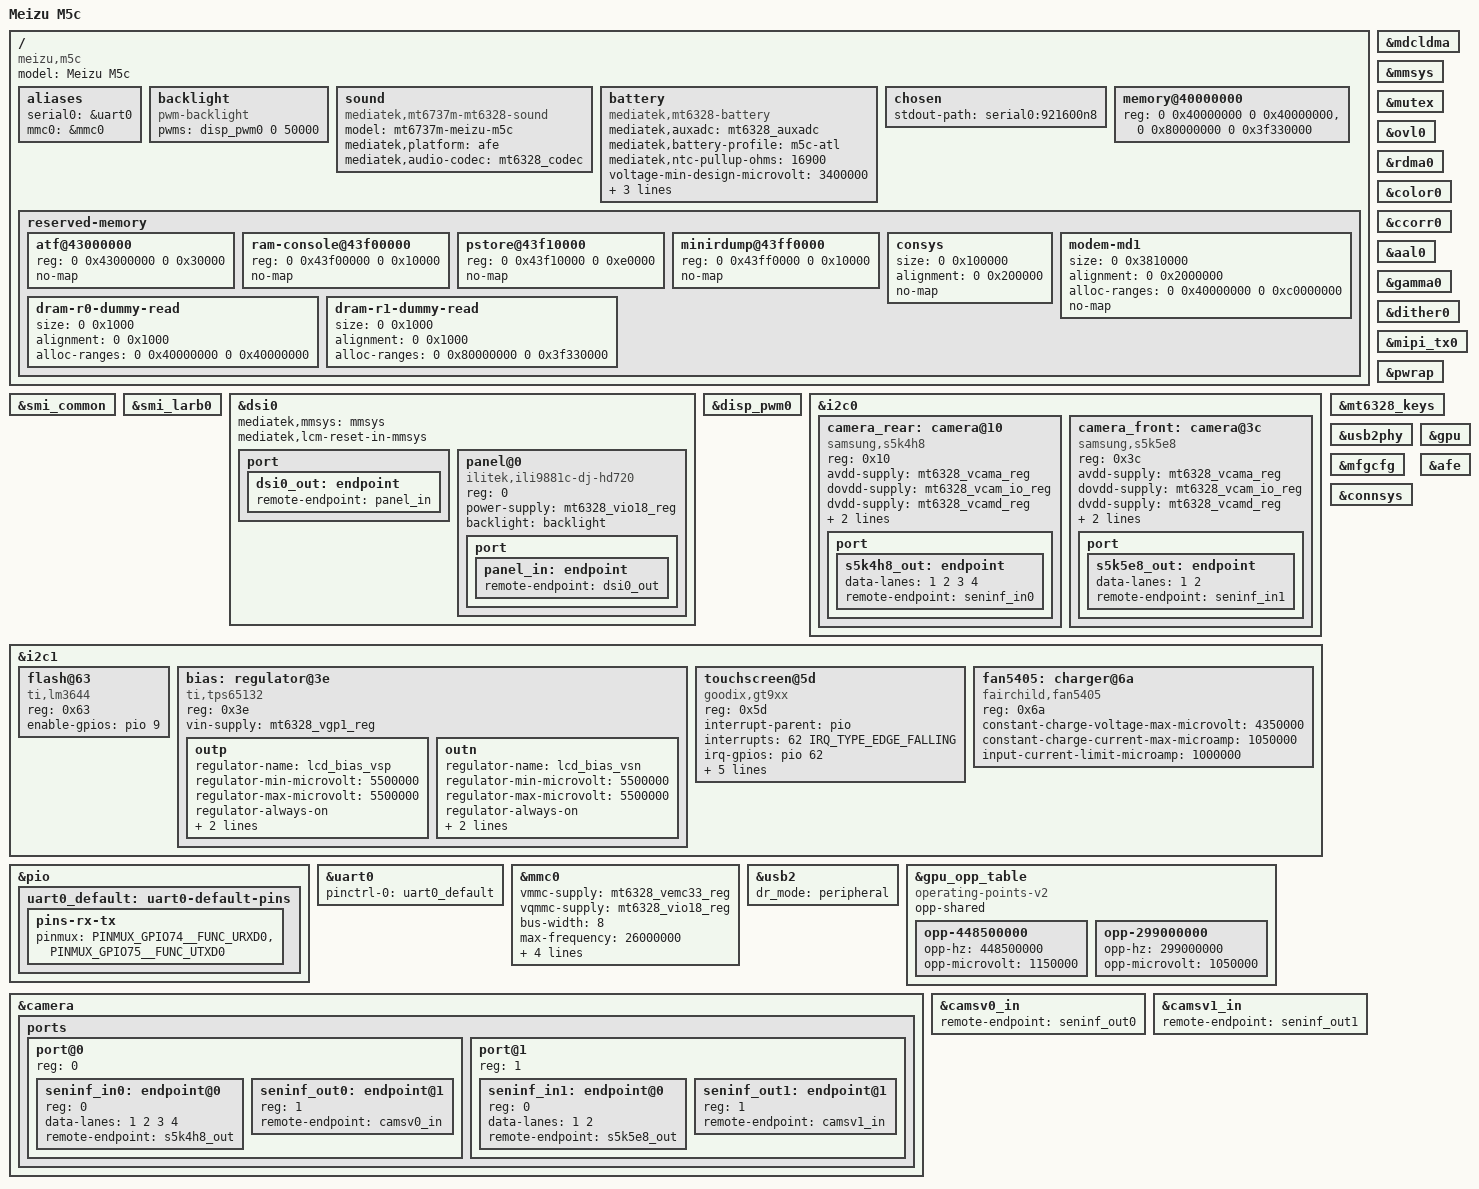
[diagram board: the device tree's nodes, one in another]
// SPDX-License-Identifier: BSD-3-Clause
/dts-v1/;

#include <dt-bindings/gpio/gpio.h>

#include "mt6737m.dtsi"
#include "mt6328.dtsi"

/ {
	model = "Meizu M5c";
	compatible = "meizu,m5c", "mediatek,mt6737m";

	aliases {
		serial0 = &uart0;
		mmc0 = &mmc0;
	};

	/*
	 * Backlight on DISP_PWM channel 0.
	 * UNPROVEN: the stock board only provides led_mode = <5> and
	 * pwm_config = <0 0 0 0 0>; the 20 kHz period is a placeholder and
	 * the PWM output pin/pinmux is not known yet.
	 */
	backlight: backlight {
		compatible = "pwm-backlight";
		pwms = <&disp_pwm0 0 50000>;
	};

	sound {
		compatible = "mediatek,mt6737m-mt6328-sound";
		model = "mt6737m-meizu-m5c";
		mediatek,platform = <&afe>;
		mediatek,audio-codec = <&mt6328_codec>;
	};

	battery: battery {
		compatible = "mediatek,mt6328-battery";
		mediatek,auxadc = <&mt6328_auxadc>;
		mediatek,battery-profile = "m5c-atl";
		mediatek,ntc-pullup-ohms = <16900>;
		voltage-min-design-microvolt = <3400000>;
		voltage-max-design-microvolt = <4350000>;
		charge-current-max-microamp = <1050000>;
		charger = <&fan5405>;
	};

	chosen {
		stdout-path = "serial0:921600n8";
	};

	memory@40000000 {
		device_type = "memory";
		reg = <0 0x40000000 0 0x40000000>,
		      <0 0x80000000 0 0x3f330000>;
	};

	reserved-memory {
		#address-cells = <2>;
		#size-cells = <2>;
		ranges;

		atf@43000000 {
			reg = <0 0x43000000 0 0x30000>;
			no-map;
		};

		ram-console@43f00000 {
			reg = <0 0x43f00000 0 0x10000>;
			no-map;
		};

		pstore@43f10000 {
			reg = <0 0x43f10000 0 0xe0000>;
			no-map;
		};

		minirdump@43ff0000 {
			reg = <0 0x43ff0000 0 0x10000>;
			no-map;
		};

		consys {
			size = <0 0x100000>;
			alignment = <0 0x200000>;
			no-map;
		};

		/*
		 * MD1 cellular modem DRAM: firmware image plus the shared
		 * memory window in one contiguous extents (vendor
		 * reserve-memory-ccci_md1 size = md_size+smem_size,
		 * 0x3810000 bytes). Linux must never allocate from it.
		 */
		modem-md1 {
			size = <0 0x3810000>;
			alignment = <0 0x2000000>;
			alloc-ranges = <0 0x40000000 0 0xc0000000>;
			no-map;
		};

		dram-r0-dummy-read {
			size = <0 0x1000>;
			alignment = <0 0x1000>;
			alloc-ranges = <0 0x40000000 0 0x40000000>;
		};

		dram-r1-dummy-read {
			size = <0 0x1000>;
			alignment = <0 0x1000>;
			alloc-ranges = <0 0x80000000 0 0x3f330000>;
		};
	};
};

/*
 * MD1 cellular modem. The CLDMA and CCIF blocks come from the mt6735.dtsi
 * node; this board only has to enable it, the transport clocks are optional.
 */
&mdcldma {
	status = "okay";
};

/*
 * Display skeleton for the m5c (MT6737M).  All register data comes from the
 * vendor 4.9 tree; this has never been run on hardware.  There is no
 * power-domains/scpsys node yet and no SMI larb0/iommu, so the DISP domain
 * and the SMI gates are left as LK configured them.
 */
&mmsys {
	status = "okay";
};

&smi_common {
	status = "okay";
};

&smi_larb0 {
	status = "okay";
};

&mutex {
	status = "okay";
};

&ovl0 {
	status = "okay";
};

&rdma0 {
	status = "okay";
};

&color0 {
	status = "okay";
};

&ccorr0 {
	status = "okay";
};

&aal0 {
	status = "okay";
};

&gamma0 {
	status = "okay";
};

&dither0 {
	status = "okay";
};

/*
 * DSI0: the panel reset is MMSYS+0x150 bit 0 (LCM_RST_B), not a GPIO, see
 * the mtk_dsi quirk.  Panel timing/init table live in
 * panel-ilitek-ili9881c.c (ilitek,ili9881c-dj-hd720).
 */
&dsi0 {
	status = "okay";
	mediatek,mmsys = <&mmsys>;
	mediatek,lcm-reset-in-mmsys;

	port {
		dsi0_out: endpoint {
			remote-endpoint = <&panel_in>;
		};
	};

	panel@0 {
		compatible = "ilitek,ili9881c-dj-hd720";
		reg = <0>;

		/*
		 * UNPROVEN: VGP1 is what the vendor switches in lcm_init_power()
		 * and is used here as the bias chip VIN; the panel VDDI/IOVCC is
		 * assumed to be the always-on VIO18 rail.  The panel driver only
		 * models one supply.
		 */
		power-supply = <&mt6328_vio18_reg>;
		backlight = <&backlight>;

		port {
			panel_in: endpoint {
				remote-endpoint = <&dsi0_out>;
			};
		};
	};
};

&mipi_tx0 {
	status = "okay";
};

&disp_pwm0 {
	status = "okay";
};

&i2c0 {
	status = "okay";

	/*
	 * Rear camera: Samsung S5K4H8 (8 Mpix, 4-lane CSI-2) at 0x10 on i2c0.
	 * Stock pins: CMRST = GPIO44, CMPDN = GPIO7.
	 */
	camera_rear: camera@10 {
		compatible = "samsung,s5k4h8";
		reg = <0x10>;
		avdd-supply = <&mt6328_vcama_reg>;
		dovdd-supply = <&mt6328_vcam_io_reg>;
		dvdd-supply = <&mt6328_vcamd_reg>;
		reset-gpios = <&pio 44 GPIO_ACTIVE_LOW>;
		powerdown-gpios = <&pio 7 GPIO_ACTIVE_LOW>;

		port {
			s5k4h8_out: endpoint {
				data-lanes = <1 2 3 4>;
				remote-endpoint = <&seninf_in0>;
			};
		};
	};

	/*
	 * Front camera: Samsung S5K5E8 (5 Mpix, 2-lane CSI-2) at 0x3c on i2c0.
	 * Stock pins: CMRST1 = GPIO11, CMPDN1 = GPIO12.
	 */
	camera_front: camera@3c {
		compatible = "samsung,s5k5e8";
		reg = <0x3c>;
		avdd-supply = <&mt6328_vcama_reg>;
		dovdd-supply = <&mt6328_vcam_io_reg>;
		dvdd-supply = <&mt6328_vcamd_reg>;
		reset-gpios = <&pio 11 GPIO_ACTIVE_LOW>;
		powerdown-gpios = <&pio 12 GPIO_ACTIVE_LOW>;

		port {
			s5k5e8_out: endpoint {
				data-lanes = <1 2>;
				remote-endpoint = <&seninf_in1>;
			};
		};
	};
};

&i2c1 {
	status = "okay";

	/*
	 * Rear camera flash controller (stock strobe_main@63 on i2c1,
	 * hardware enable on GPIO9).
	 */
	flash@63 {
		compatible = "ti,lm3644", "mediatek,strobe_main";
		reg = <0x63>;
		enable-gpios = <&pio 9 GPIO_ACTIVE_HIGH>;
	};

	/*
	 * TPS65132 bias.  Vendor: i2c1 0x3e, ENP GPIO64, ENN GPIO63, both
	 * driven high to enable (bridge-stock.dts:2327-2368).
	 */
	bias: regulator@3e {
		compatible = "ti,tps65132";
		reg = <0x3e>;
		vin-supply = <&mt6328_vgp1_reg>;

		outp {
			regulator-name = "lcd_bias_vsp";
			/* vendor writes reg 0x00 = 0x0f -> 4.0 V + 15 * 100 mV */
			regulator-min-microvolt = <5500000>;
			regulator-max-microvolt = <5500000>;
			regulator-always-on;
			enable-gpios = <&pio 64 GPIO_ACTIVE_HIGH>;
			/* driver requires the property even without a discharge GPIO */
			ti,active-discharge-time-us = <0>;
		};

		outn {
			regulator-name = "lcd_bias_vsn";
			/* vendor writes reg 0x01 = 0x0f -> -5.5 V */
			regulator-min-microvolt = <5500000>;
			regulator-max-microvolt = <5500000>;
			regulator-always-on;
			enable-gpios = <&pio 63 GPIO_ACTIVE_HIGH>;
			ti,active-discharge-time-us = <0>;
		};
	};

	/*
	 * GT9XXTB touch.  Vendor: i2c1 0x5d, EINT GPIO62, reset GPIO10.
	 * The mainline goodix driver reads the id string at runtime
	 * ("GT9XXTB..." on this panel), so gt911 is only the match fallback.
	 * reset-gpios and irq-gpios are ACTIVE_HIGH because the goodix driver
	 * drives both lines freely during its reset/address-strap sequence.
	 */
	touchscreen@5d {
		compatible = "goodix,gt9xx", "goodix,gt911";
		reg = <0x5d>;
		interrupt-parent = <&pio>;
		interrupts = <62 IRQ_TYPE_EDGE_FALLING>;
		interrupt-names = "irq";
		irq-gpios = <&pio 62 GPIO_ACTIVE_HIGH>;
		reset-gpios = <&pio 10 GPIO_ACTIVE_HIGH>;
		AVDD28-supply = <&mt6328_vgp1_reg>;
		VDDIO-supply = <&mt6328_vio18_reg>;
		touchscreen-size-x = <720>;
		touchscreen-size-y = <1280>;
	};

	/* Fairchild FAN5405 switching charger on i2c1 @ 0x6a */
	fan5405: charger@6a {
		compatible = "fairchild,fan5405";
		reg = <0x6a>;
		constant-charge-voltage-max-microvolt = <4350000>;
		constant-charge-current-max-microamp = <1050000>;
		input-current-limit-microamp = <1000000>;
	};

};

&pio {
	uart0_default: uart0-default-pins {
		pins-rx-tx {
			pinmux = <PINMUX_GPIO74__FUNC_URXD0>,
				 <PINMUX_GPIO75__FUNC_UTXD0>;
		};
	};
};

&uart0 {
	pinctrl-names = "default";
	pinctrl-0 = <&uart0_default>;
	status = "okay";
};

&pwrap {
	status = "okay";
};

&mt6328_keys {
	status = "okay";
};

&mmc0 {
	vmmc-supply = <&mt6328_vemc33_reg>;
	vqmmc-supply = <&mt6328_vio18_reg>;
	bus-width = <8>;
	max-frequency = <26000000>;
	non-removable;
	disable-wp;
	no-sd;
	no-sdio;
	status = "okay";
};

&usb2 {
	dr_mode = "peripheral";
	status = "okay";
};

&usb2phy {
	status = "okay";
};

/*
 * Mali-T720MP3 GPU (MT6737M).
 *
 * Addresses, interrupts and clock come from the stock MT6735-family DTS
 * (kernel-m5c-4.9-lc mt6735m.dts: MFGCFG@0x13000000, MALI@0x13040000 with
 * SPI 212/211/210 and clock-frequency 450 MHz); the 450 MHz bin is the
 * "LV1: 450 MHz for HPM" GPU DVFS profile of the same tree
 * (drivers/misc/mediatek/base/power/mt6735/mt_gpufreq.c:274-285,
 * GPU_DVFS_FREQ1 = 448500 kHz / 1150 mV, GPU_DVFS_FREQ2 = 299000 kHz).
 *
 * VGPU is the MT6328 BUCK_VPROC output on the MT6735 platform (the PMIC
 * has no dedicated VGPU buck), so it is not attached as an OPP regulator:
 * devfreq only scales mfg_sel and the rail stays at the LK value.
 *
 * mfgcfg is enabled together with the GPU because the gate lives in the
 * MFG MTCMOS domain; panfrost powers that domain through its
 * power-domains before the gate is ever touched.
 */
&mfgcfg {
	status = "okay";
};

&gpu {
	status = "okay";
};

/*
 * OPP table from the MT6735/MT6737M mt_gpufreq.c "HPM 450 MHz" profile
 * (mt_gpufreq_opp_tbl_e1_1[], GPUOP(GPU_DVFS_FREQ1, GPU_DVFS_VOLT1),
 * GPUOP(GPU_DVFS_FREQ2, GPU_DVFS_VOLT2)). The 650 MHz "LV2" /
 * "LV4 500 MHz" bins exist only for D2+ speed-binned parts and are not
 * assumed here.
 */
&gpu_opp_table {
	compatible = "operating-points-v2";
	opp-shared;

	opp-448500000 {
		opp-hz = /bits/ 64 <448500000>;
		opp-microvolt = <1150000>;
	};

	opp-299000000 {
		opp-hz = /bits/ 64 <299000000>;
		opp-microvolt = <1050000>;
	};
};

 /*
 * Integrated CONSYS (Wi-Fi/BT/GPS).  The MCU clock gate and the top AXI
 * protection block are owned by the firmware until the kernel takes the
 * subsystem over through /dev/wmtdetect, so the node stays disabled until
 * the connectivity stack is brought up by userspace.
 */
&connsys {
	status = "okay";
};

&afe {
	status = "okay";
};

&camera {
	status = "okay";

	ports {
		#address-cells = <1>;
		#size-cells = <0>;

		port@0 {
			reg = <0>;
			#address-cells = <1>;
			#size-cells = <0>;

			seninf_in0: endpoint@0 {
				reg = <0>;
				data-lanes = <1 2 3 4>;
				remote-endpoint = <&s5k4h8_out>;
			};

			seninf_out0: endpoint@1 {
				reg = <1>;
				remote-endpoint = <&camsv0_in>;
			};
		};

		port@1 {
			reg = <1>;
			#address-cells = <1>;
			#size-cells = <0>;

			seninf_in1: endpoint@0 {
				reg = <0>;
				data-lanes = <1 2>;
				remote-endpoint = <&s5k5e8_out>;
			};

			seninf_out1: endpoint@1 {
				reg = <1>;
				remote-endpoint = <&camsv1_in>;
			};
		};
	};
};

&camsv0_in {
	remote-endpoint = <&seninf_out0>;
};

&camsv1_in {
	remote-endpoint = <&seninf_out1>;
};
